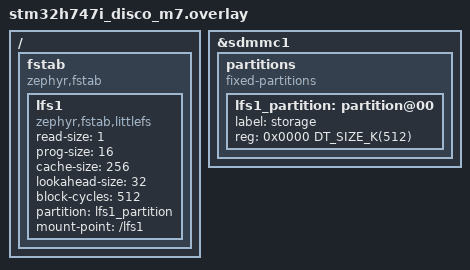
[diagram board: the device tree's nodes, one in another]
/*
 * Copyright (c) 2022 Christoph Heller
 *
 * SPDX-License-Identifier: Apache-2.0
 */

&sdmmc1 {
	partitions {
		compatible = "fixed-partitions";
		#address-cells = <1>;
		#size-cells = <1>;

		/* Use half of flash for the filesystem. */
		lfs1_partition: partition@00 {
			label = "storage";
			reg = <0x0000 DT_SIZE_K(512)>;
		};

	};
};

/ {
	fstab {
		compatible = "zephyr,fstab";
		lfs1: lfs1 {
			compatible = "zephyr,fstab,littlefs";
			read-size = <1>;
			prog-size = <16>;
			cache-size = <256>;
			lookahead-size = <32>;
			block-cycles = <512>;
			partition = <&lfs1_partition>;
			mount-point = "/lfs1";
    };
	};
};
